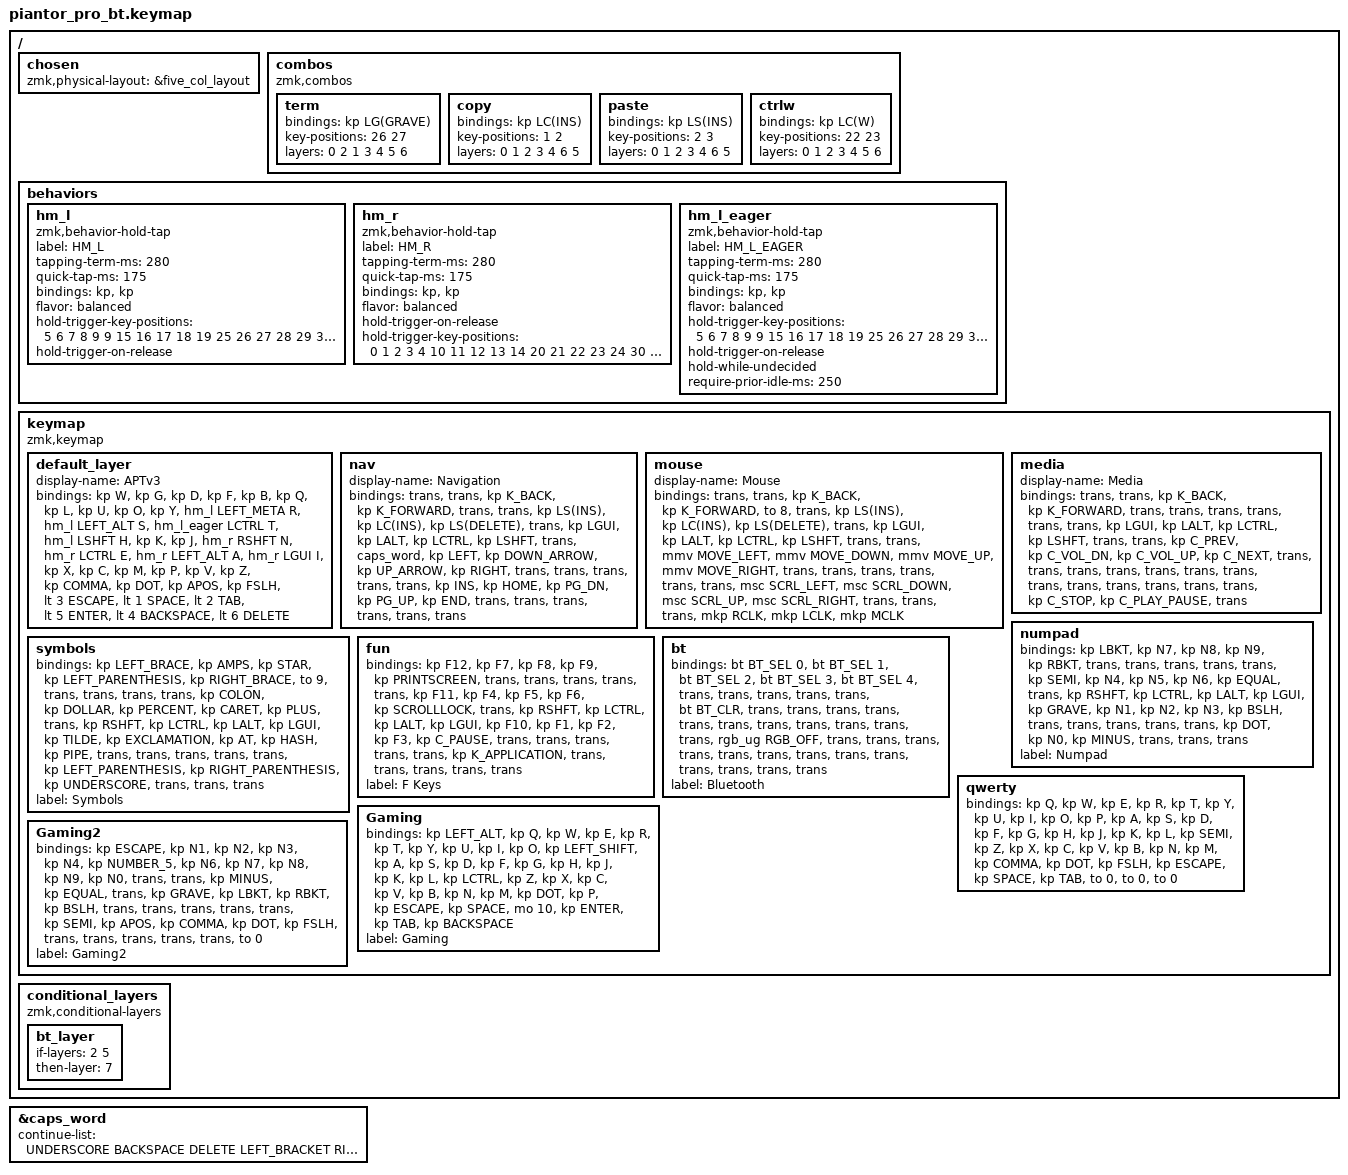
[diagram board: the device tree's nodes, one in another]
/*
 * Copyright (c) 2020 The ZMK Contributors
 *
 * SPDX-License-Identifier: MIT
 */

#include <behaviors.dtsi>
#include <dt-bindings/zmk/bt.h>
#include <dt-bindings/zmk/keys.h>
#include <dt-bindings/zmk/pointing.h>
#include <dt-bindings/zmk/rgb.h>

&caps_word { continue-list = <UNDERSCORE BACKSPACE DELETE LEFT_BRACKET RIGHT_BRACKET EQUAL BACKSLASH GRAVE LSHIFT RSHIFT>; };

/ {
    chosen { zmk,physical-layout = &five_col_layout; };
};

/ {
    combos {
        compatible = "zmk,combos";

        term {
            bindings = <&kp LG(GRAVE)>;
            key-positions = <26 27>;
            layers = <0 2 1 3 4 5 6>;
        };

        copy {
            bindings = <&kp LC(INS)>;
            key-positions = <1 2>;
            layers = <0 1 2 3 4 6 5>;
        };

        paste {
            bindings = <&kp LS(INS)>;
            key-positions = <2 3>;
            layers = <0 1 2 3 4 6 5>;
        };

        ctrlw {
            bindings = <&kp LC(W)>;
            key-positions = <22 23>;
            layers = <0 1 2 3 4 5 6>;
        };
    };

    behaviors {
        hm_l: hm_l {
            compatible = "zmk,behavior-hold-tap";
            label = "HM_L";
            #binding-cells = <2>;
            tapping-term-ms = <280>;
            quick-tap-ms = <175>;
            bindings = <&kp>, <&kp>;

            flavor = "balanced";
            hold-trigger-key-positions = <5 6 7 8 9 9 15 16 17 18 19 25 26 27 28 29 30 31 32 33 34 35>;
            hold-trigger-on-release;
        };

        hm_r: hm_r {
            compatible = "zmk,behavior-hold-tap";
            label = "HM_R";
            #binding-cells = <2>;
            tapping-term-ms = <280>;
            quick-tap-ms = <175>;
            bindings = <&kp>, <&kp>;

            flavor = "balanced";
            hold-trigger-on-release;
            hold-trigger-key-positions = <0 1 2 3 4 10 11 12 13 14 20 21 22 23 24 30 31 32 33 34 35>;
        };

        hm_l_eager: hm_l_eager {
            compatible = "zmk,behavior-hold-tap";
            label = "HM_L_EAGER";
            #binding-cells = <2>;
            tapping-term-ms = <280>;
            quick-tap-ms = <175>;
            bindings = <&kp>, <&kp>;

            flavor = "balanced";
            hold-trigger-key-positions = <5 6 7 8 9 9 15 16 17 18 19 25 26 27 28 29 30 31 32 33 34 35>;
            hold-trigger-on-release;
            hold-while-undecided;
            require-prior-idle-ms = <250>;
        };
    };

    keymap {
        compatible = "zmk,keymap";

        default_layer {
            display-name = "APTv3";

            // --------------------------------------------------------------
            // |  Q  |  W  |  E  |  R  |  T  |  Y  |  U   |  I  |  O  |  P  |
            // |  A  |  S  |  D  |  F  |  G  |  H  |  J   |  K  |  L  |  ;  |
            // |  Z  |  X  |  C  |  V  |  B  |  N  |  M   |  ,  |  .  |  /  |
            //                    | GUI | LWR | SPC | ENT | RSE  | ALT |

            bindings = <
  &kp W  &kp G  &kp D  &kp F  &kp B  &kp Q  &kp L  &kp U  &kp O  &kp Y      &hm_l LEFT_META R  &hm_l LEFT_ALT S  &hm_l_eager LCTRL T  &hm_l LSHFT H  &kp K  &kp J  &hm_r RSHFT N  &hm_r LCTRL E  &hm_r LEFT_ALT A  &hm_r LGUI I      &kp X  &kp C  &kp M  &kp P  &kp V  &kp Z  &kp COMMA  &kp DOT  &kp APOS  &kp FSLH    &lt 3 ESCAPE  &lt 1 SPACE  &lt 2 TAB  &lt 5 ENTER  &lt 4 BACKSPACE  &lt 6 DELETE
            >;
        };

        nav {
            display-name = "Navigation";
            bindings = <
  &trans  &trans  &kp K_BACK  &kp K_FORWARD  &trans  &trans  &kp LS(INS)  &kp LC(INS)  &kp LS(DELETE)  &trans      &kp LGUI  &kp LALT  &kp LCTRL  &kp LSHFT  &trans  &caps_word  &kp LEFT  &kp DOWN_ARROW  &kp UP_ARROW  &kp RIGHT      &trans  &trans  &trans  &trans  &trans  &kp INS  &kp HOME  &kp PG_DN  &kp PG_UP  &kp END    &trans  &trans  &trans  &trans  &trans  &trans
            >;
        };

        mouse {
            display-name = "Mouse";
            bindings = <
  &trans  &trans  &kp K_BACK  &kp K_FORWARD  &to 8  &trans  &kp LS(INS)  &kp LC(INS)  &kp LS(DELETE)  &trans      &kp LGUI  &kp LALT  &kp LCTRL  &kp LSHFT  &trans  &trans  &mmv MOVE_LEFT  &mmv MOVE_DOWN  &mmv MOVE_UP  &mmv MOVE_RIGHT      &trans  &trans  &trans  &trans  &trans  &trans  &msc SCRL_LEFT  &msc SCRL_DOWN  &msc SCRL_UP  &msc SCRL_RIGHT    &trans  &trans  &trans  &mkp RCLK  &mkp LCLK  &mkp MCLK
            >;
        };

        media {
            display-name = "Media";
            bindings = <
  &trans  &trans  &kp K_BACK  &kp K_FORWARD  &trans  &trans  &trans  &trans  &trans  &trans      &kp LGUI  &kp LALT  &kp LCTRL  &kp LSHFT  &trans  &trans  &kp C_PREV  &kp C_VOL_DN  &kp C_VOL_UP  &kp C_NEXT      &trans  &trans  &trans  &trans  &trans  &trans  &trans  &trans  &trans  &trans    &trans  &trans  &trans  &kp C_STOP  &kp C_PLAY_PAUSE  &trans
            >;
        };

        numpad {
            bindings = <
  &kp LBKT  &kp N7  &kp N8  &kp N9  &kp RBKT  &trans  &trans  &trans  &trans  &trans      &kp SEMI  &kp N4  &kp N5  &kp N6  &kp EQUAL  &trans  &kp RSHFT  &kp LCTRL  &kp LALT  &kp LGUI      &kp GRAVE  &kp N1  &kp N2  &kp N3  &kp BSLH  &trans  &trans  &trans  &trans  &trans    &kp DOT  &kp N0  &kp MINUS  &trans  &trans  &trans
            >;

            label = "Numpad";
        };

        symbols {
            bindings = <
  &kp LEFT_BRACE  &kp AMPS  &kp STAR  &kp LEFT_PARENTHESIS  &kp RIGHT_BRACE  &to 9  &trans  &trans  &trans  &trans      &kp COLON  &kp DOLLAR  &kp PERCENT  &kp CARET  &kp PLUS  &trans  &kp RSHFT  &kp LCTRL  &kp LALT  &kp LGUI      &kp TILDE  &kp EXCLAMATION  &kp AT  &kp HASH  &kp PIPE  &trans  &trans  &trans  &trans  &trans    &kp LEFT_PARENTHESIS  &kp RIGHT_PARENTHESIS  &kp UNDERSCORE  &trans  &trans  &trans
            >;

            label = "Symbols";
        };

        fun {
            bindings = <
  &kp F12  &kp F7  &kp F8  &kp F9  &kp PRINTSCREEN  &trans  &trans  &trans  &trans  &trans      &kp F11  &kp F4  &kp F5  &kp F6  &kp SCROLLLOCK  &trans  &kp RSHFT  &kp LCTRL  &kp LALT  &kp LGUI      &kp F10  &kp F1  &kp F2  &kp F3  &kp C_PAUSE  &trans  &trans  &trans  &trans  &trans    &kp K_APPLICATION  &trans  &trans  &trans  &trans  &trans
            >;

            label = "F Keys";
        };

        bt {
            bindings = <
  &bt BT_SEL 0  &bt BT_SEL 1  &bt BT_SEL 2  &bt BT_SEL 3  &bt BT_SEL 4  &trans  &trans  &trans  &trans  &trans      &bt BT_CLR  &trans  &trans  &trans  &trans  &trans  &trans  &trans  &trans  &trans      &trans  &trans  &rgb_ug RGB_OFF  &trans  &trans  &trans  &trans  &trans  &trans  &trans    &trans  &trans  &trans  &trans  &trans  &trans
            >;

            label = "Bluetooth";
        };

        qwerty {
            bindings = <
  &kp Q  &kp W  &kp E  &kp R  &kp T  &kp Y  &kp U  &kp I  &kp O  &kp P      &kp A  &kp S  &kp D  &kp F  &kp G  &kp H  &kp J  &kp K  &kp L  &kp SEMI      &kp Z  &kp X  &kp C  &kp V  &kp B  &kp N  &kp M  &kp COMMA  &kp DOT  &kp FSLH    &kp ESCAPE  &kp SPACE  &kp TAB  &to 0  &to 0  &to 0
            >;
        };

        Gaming {
            bindings = <
  &kp LEFT_ALT  &kp Q  &kp W  &kp E  &kp R  &kp T  &kp Y  &kp U  &kp I  &kp O      &kp LEFT_SHIFT  &kp A  &kp S  &kp D  &kp F  &kp G  &kp H  &kp J  &kp K  &kp L      &kp LCTRL  &kp Z  &kp X  &kp C  &kp V  &kp B  &kp N  &kp M  &kp DOT  &kp P    &kp ESCAPE  &kp SPACE  &mo 10  &kp ENTER  &kp TAB  &kp BACKSPACE
            >;

            label = "Gaming";
        };

        Gaming2 {
            bindings = <
  &kp ESCAPE  &kp N1  &kp N2  &kp N3  &kp N4  &kp NUMBER_5  &kp N6  &kp N7  &kp N8  &kp N9      &kp N0  &trans  &trans  &kp MINUS  &kp EQUAL  &trans  &kp GRAVE  &kp LBKT  &kp RBKT  &kp BSLH      &trans  &trans  &trans  &trans  &trans  &kp SEMI  &kp APOS  &kp COMMA  &kp DOT  &kp FSLH    &trans  &trans  &trans  &trans  &trans  &to 0
            >;

            label = "Gaming2";
        };
    };

    conditional_layers {
        compatible = "zmk,conditional-layers";

        bt_layer {
            if-layers = <2 5>;
            then-layer = <7>;
        };
    };
};
